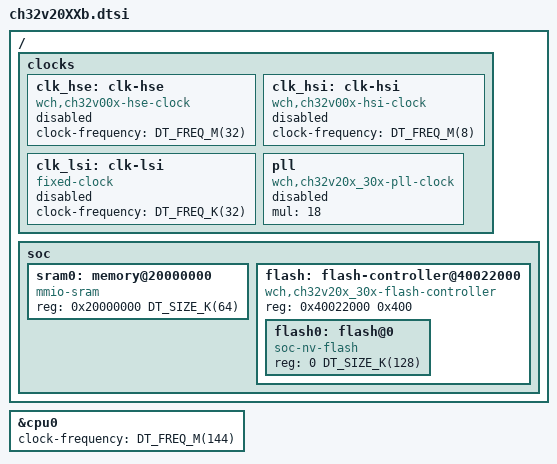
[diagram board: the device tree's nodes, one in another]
/*
 * Copyright (c) 2025 Jianxiong Gu <jianxiong.gu@outlook.com>
 *
 * SPDX-License-Identifier: Apache-2.0
 */

#include <freq.h>
#include <mem.h>

/ {
	clocks {
		clk_hse: clk-hse {
			#clock-cells = <0>;
			compatible = "wch,ch32v00x-hse-clock";
			clock-frequency = <DT_FREQ_M(32)>;
			status = "disabled";
		};

		clk_hsi: clk-hsi {
			#clock-cells = <0>;
			compatible = "wch,ch32v00x-hsi-clock";
			clock-frequency = <DT_FREQ_M(8)>;
			status = "disabled";
		};

		clk_lsi: clk-lsi {
			#clock-cells = <0>;
			compatible = "fixed-clock";
			clock-frequency = <DT_FREQ_K(32)>;
			status = "disabled";
		};

		pll: pll {
			#clock-cells = <0>;
			compatible = "wch,ch32v20x_30x-pll-clock";
			mul = <18>;
			status = "disabled";
		};
	};

	soc {
		sram0: memory@20000000 {
			compatible = "mmio-sram";
			reg = <0x20000000 DT_SIZE_K(64)>;
		};

		flash: flash-controller@40022000 {
			compatible = "wch,ch32v20x_30x-flash-controller";
			reg = <0x40022000 0x400>;
			#address-cells = <1>;
			#size-cells = <1>;

			flash0: flash@0 {
				compatible = "soc-nv-flash";
				reg = <0 DT_SIZE_K(128)>;
			};
		};
	};
};

&cpu0 {
	clock-frequency = <DT_FREQ_M(144)>;
};
